# MKM32Z5 register map
File version: 1.6
Registers are 8-bit, read-write, reset 0x0 unless marked. A register's access mark holds for its fields unless they carry their own. Offsets are from the block's base; [hi:lo] are bit positions; {n}, {i} and the like mark numbered series; 'fields as' and 'values as' point back to an identical list.

## MTB — Micro Trace Buffer
Base 0xF0000000; register names take the prefix MTB_
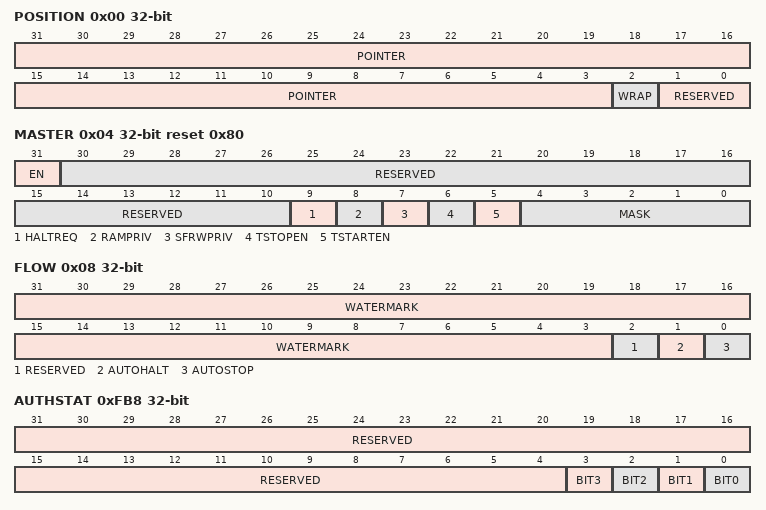
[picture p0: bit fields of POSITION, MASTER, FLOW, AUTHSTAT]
0x00 POSITION 32-bit (reset mask 0x3) — MTB Position Register
  [31:3] POINTER — Trace Packet Address Pointer[28:0]
  [2] WRAP
  [1:0] RESERVED ro
0x04 MASTER 32-bit reset 0x80 (reset mask 0xFFFFFFE0) — MTB Master Register
  [31] EN — Main Trace Enable
  [30:10] RESERVED ro
  [9] HALTREQ — Halt Request
  [8] RAMPRIV — RAM Privilege
  [7] SFRWPRIV — Special Function Register Write Privilege
  [6] TSTOPEN — Trace Stop Input Enable
  [5] TSTARTEN — Trace Start Input Enable
  [4:0] MASK
0x08 FLOW 32-bit (reset mask 0x4) — MTB Flow Register
  [31:3] WATERMARK — WATERMARK[28:0]
  [2] RESERVED ro
  [1] AUTOHALT
  [0] AUTOSTOP
0x0C BASE 32-bit ro reset not defined — MTB Base Register
  [31:0] BASEADDR
0xF00 MODECTRL 32-bit ro — Integration Mode Control Register
0xFA0 TAGSET 32-bit ro — Claim TAG Set Register
0xFA4 TAGCLEAR 32-bit ro — Claim TAG Clear Register
0xFB0 LOCKACCESS 32-bit ro
0xFB4 LOCKSTAT 32-bit ro — Lock Status Register
0xFB8 AUTHSTAT 32-bit ro — Authentication Status Register
  [31:4] RESERVED, [n] BIT{n} (n=0..3)
0xFBC DEVICEARCH 32-bit ro reset 0x47700A31 — Device Architecture Register
0xFC8 DEVICECFG 32-bit ro — Device Configuration Register
0xFCC DEVICETYPID 32-bit ro reset 0x31 — Device Type Identifier Register
0xFD0 PERIPHID{x} (x=4,5,6,7,0,1,2,3; step 0x4) 32-bit ro reset not defined — Peripheral ID Register
  [31:0] PERIPHID
{0xFF0+4i} COMPID{i} (i=0..3) 32-bit ro reset not defined — Component ID Register
  [31:0] COMPID — Component ID

## MTBDWT — MTB data watchpoint and trace
Base 0xF0001000; register names take the prefix MTBDWT_
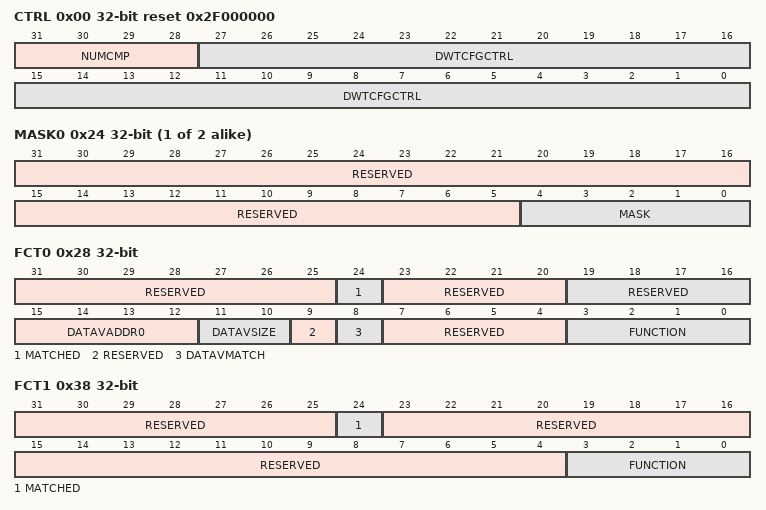
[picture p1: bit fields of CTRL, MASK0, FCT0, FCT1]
0x00 CTRL 32-bit ro reset 0x2F000000 — MTB DWT Control Register
  [31:28] NUMCMP — Number of comparators
  [27:0] DWTCFGCTRL — DWT configuration controls
{0x20+0x10*i} COMP{i} (i=0..1) 32-bit — MTB_DWT Comparator Register
  [31:0] COMP — Reference value for comparison
{0x24+0x10*i} MASK{i} (i=0..1) 32-bit — MTB_DWT Comparator Mask Register
  [31:5] RESERVED ro, [4:0] MASK
0x28 FCT0 32-bit — MTB_DWT Comparator Function Register 0
  [31:25] RESERVED ro
  [24] MATCHED ro — Comparator match
    0=No match; 1=Match occurred
  [23:20] RESERVED ro
  [19:16] RESERVED ro
  [15:12] DATAVADDR0 — Data Value Address 0
  [11:10] DATAVSIZE — Data Value Size
    0=Byte; 1=Halfword; 2=Word; 3=Reserved. Any attempts to use this value results in UNPREDICTABLE behavior.
  [9] RESERVED ro
  [8] DATAVMATCH — Data Value Match
    0=Perform address comparison; 1=Perform data value comparison
  [7:4] RESERVED ro
  [3:0] FUNCTION
    0=Disabled; 4=Instruction fetch; 5=Data operand read; 6=Data operand write; 7=Data operand (read + write)
0x38 FCT1 32-bit — MTB_DWT Comparator Function Register 1
  [31:25] RESERVED ro
  [24] MATCHED ro — Comparator match
    0=No match; 1=Match occurred
  [23:4] RESERVED ro
  [3:0] FUNCTION
    values as FCT0.FUNCTION
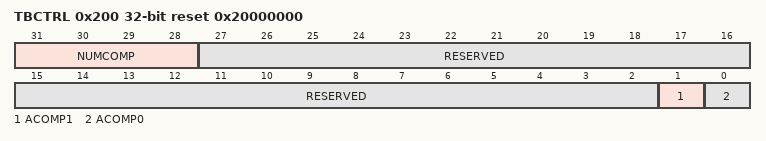
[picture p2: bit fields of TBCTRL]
0x200 TBCTRL 32-bit reset 0x20000000 — MTB_DWT Trace Buffer Control Register
  [31:28] NUMCOMP ro — Number of Comparators
  [27:2] RESERVED ro
  [1] ACOMP1 — Action based on Comparator 1 match
    0=Trigger TSTOP based on the assertion of MTBDWT_FCT1[MATCHED]; 1=Trigger TSTART based on the assertion of MTBDWT_FCT1[MATCHED]
  [0] ACOMP0 — Action based on Comparator 0 match
    0=Trigger TSTOP based on the assertion of MTBDWT_FCT0[MATCHED]; 1=Trigger TSTART based on the assertion of MTBDWT_FCT0[MATCHED]
0xFC8 DEVICECFG 32-bit ro — Device Configuration Register
0xFCC DEVICETYPID 32-bit ro reset 0x4 — Device Type Identifier Register
0xFD0 PERIPHID{x} (x=4,5,6,7,0,1,2,3; step 0x4) 32-bit ro reset not defined — Peripheral ID Register
  [31:0] PERIPHID
{0xFF0+4i} COMPID{i} (i=0..3) 32-bit ro reset not defined — Component ID Register
  [31:0] COMPID — Component ID
